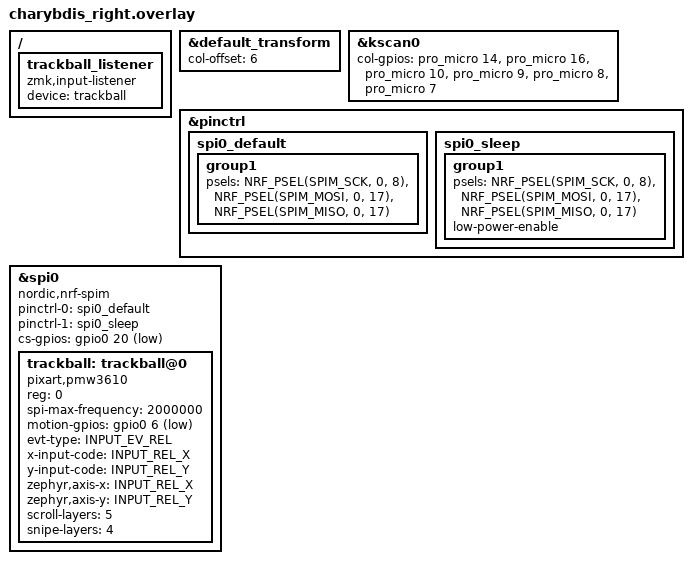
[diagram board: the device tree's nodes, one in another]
/* 형님의 끈기가 만들어낸 최종본 charybdis_right.overlay */

#include "charybdis.dtsi"
#include <dt-bindings/zmk/matrix_transform.h>
#include <dt-bindings/zmk/mouse.h>
#include <zephyr/dt-bindings/input/input-event-codes.h>

&default_transform {
    col-offset = <6>;
};

&kscan0 {
    col-gpios
        = <&pro_micro 14 GPIO_ACTIVE_HIGH>
        , <&pro_micro 16 GPIO_ACTIVE_HIGH>
        , <&pro_micro 10 GPIO_ACTIVE_HIGH>
        , <&pro_micro 9  GPIO_ACTIVE_HIGH>
        , <&pro_micro 8  GPIO_ACTIVE_HIGH>
        , <&pro_micro 7  GPIO_ACTIVE_HIGH>
        ;
};

/* 1. SPI 통신 핀 설정 (8, 17번) */
&pinctrl {
    spi0_default: spi0_default {
        group1 {
            psels = <NRF_PSEL(SPIM_SCK, 0, 8)>,
                    <NRF_PSEL(SPIM_MOSI, 0, 17)>,
                    <NRF_PSEL(SPIM_MISO, 0, 17)>;
        };
    };
    spi0_sleep: spi0_sleep {
        group1 {
            psels = <NRF_PSEL(SPIM_SCK, 0, 8)>,
                    <NRF_PSEL(SPIM_MOSI, 0, 17)>,
                    <NRF_PSEL(SPIM_MISO, 0, 17)>;
            low-power-enable;
        };
    };
};

/* 2. 트랙볼 센서 설정 (CS 20번, Motion 6번) */
&spi0 {
    status = "okay";
    compatible = "nordic,nrf-spim";
    pinctrl-0 = <&spi0_default>;
    pinctrl-1 = <&spi0_sleep>;
    pinctrl-names = "default", "sleep";
    cs-gpios = <&gpio0 20 GPIO_ACTIVE_LOW>;

    trackball: trackball@0 {
        status = "okay";
        compatible = "pixart,pmw3610";
        reg = <0>;
        spi-max-frequency = <2000000>;
        
        /* 핀 설정: Motion 6번 */
        motion-gpios = <&gpio0 6 (GPIO_ACTIVE_LOW | GPIO_PULL_UP)>;

        /* [핵심 수정] 드라이버가 딴소리 못하게 다 넣어버림 */
        /* 구버전 호환용 */
        evt-type = <INPUT_EV_REL>;
        x-input-code = <INPUT_REL_X>;
        y-input-code = <INPUT_REL_Y>;
        
        /* 신버전(Zephyr 표준) 요구사항 해결용 👇 */
        zephyr,axis-x = <INPUT_REL_X>;
        zephyr,axis-y = <INPUT_REL_Y>;

        scroll-layers = <5>;
        snipe-layers = <4>;
    };
};

/ {
  trackball_listener {
    compatible = "zmk,input-listener";
    device = <&trackball>;
  };
};
